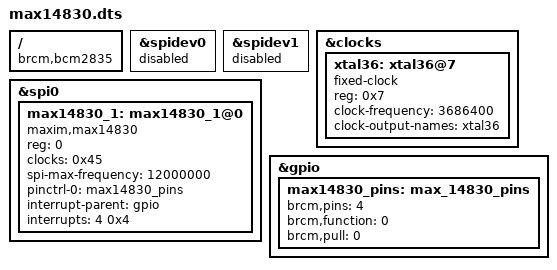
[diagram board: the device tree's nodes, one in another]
/dts-v1/;
/plugin/;
/ {
	compatible="brcm,bcm2835","brcm,bcm2836","brcm,bcm2708","brcm,bcm2709";
	
	fragment@0 {
		target = <&spidev0>;
		__overlay__ {
			status = "disabled";
		};
	};

	fragment@1 {
		target = <&spidev1>;
		__overlay__ {
			status = "disabled";
		};
	};

	fragment@2 {
		target = <&clocks>;
		__overlay__ {
			xtal36: xtal36@7 {
				reg = <0x7>;
				compatible = "fixed-clock";
				#clock-cells = <0>;
				clock-frequency = <3686400>;
				clock-output-names = "xtal36";
			};
		};
	};

	fragment@3 {
		target = <&spi0>;
		__overlay__ {
			/* needed to avoid dtc warning */
			#address-cells = <1>;
			#size-cells = <0>;
			status = "okay";
			max14830_1: max14830_1@0 {
				compatible = "maxim,max14830";
				reg = <0>; /* CE0 */
				clocks = <0x45>;
				clock-names = "xtal";
				spi-max-frequency = <12000000>;
				status = "okay";
				pinctrl-names = "default";
				pinctrl-0 = <&max14830_pins>;
				interrupt-parent = <&gpio>;
				interrupts = <4 0x4>; /* falling edge */
			};
		};
	};

	fragment@4 {
		target = <&gpio>;
		__overlay__ {
			max14830_pins: max_14830_pins {
				brcm,pins = <4>;
				brcm,function = <0>; /* in */
				brcm,pull = <0>; /* none */
			};
		};
	};

	__overrides__ {
		int_pin = <&max14830_1>, "interrupts:0",
				<&max14830_pins>, "brcm,pins:0";
		speed   = <&max14830_1>, "spi-max-frequency:0";
	};
};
